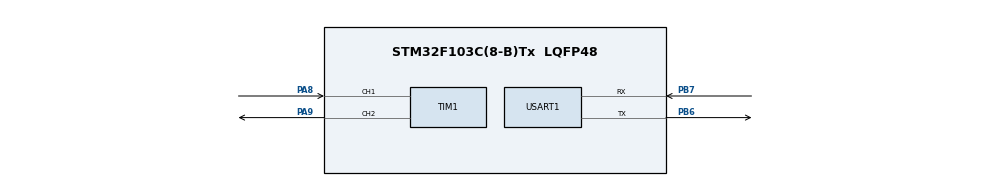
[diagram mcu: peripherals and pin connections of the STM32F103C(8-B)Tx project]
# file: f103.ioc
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Mcu.Family=STM32F1
Mcu.Name=STM32F103C(8-B)Tx
Mcu.Package=LQFP48
NVIC.PriorityGroup=NVIC_PRIORITYGROUP_4
PA13.Mode=Serial_Wire
PA13.Signal=SYS_JTMS-SWDIO
PA14.Mode=Serial_Wire
PA14.Signal=SYS_JTCK-SWCLK
PA8.Signal=S_TIM1_CH1
PA9.Signal=S_TIM1_CH2
PB6.Mode=Asynchronous
PB6.Signal=USART1_TX
PB7.Mode=Asynchronous
PB7.Signal=USART1_RX
PD0-OSC_IN.Mode=HSE-External-Oscillator
PD0-OSC_IN.Signal=RCC_OSC_IN
PD1-OSC_OUT.Mode=HSE-External-Oscillator
PD1-OSC_OUT.Signal=RCC_OSC_OUT
ProjectManager.HeapSize=0x200
ProjectManager.StackSize=0x400
ProjectManager.TargetToolchain=CMake
RCC.APB1Freq_Value=8000000
RCC.APB2Freq_Value=8000000
SH.S_TIM1_CH1.0=TIM1_CH1,Input_Capture1_from_TI1
SH.S_TIM1_CH2.0=TIM1_CH2,Output Compare2 CH2
TIM1.Channel-Input_Capture1_from_TI1=TIM_CHANNEL_1
TIM1.Channel-Output\ Compare2\ CH2=TIM_CHANNEL_2
USART1.VirtualMode=VM_ASYNC
board=custom

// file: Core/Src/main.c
/* USER CODE BEGIN Header */
/**
  ******************************************************************************
  * @file           : main.c
  * @brief          : Main program body
  ******************************************************************************
  * @attention
  *
  * Copyright (c) 2026 STMicroelectronics.
  * All rights reserved.
  *
  * This software is licensed under terms that can be found in the LICENSE file
  * in the root directory of this software component.
  * If no LICENSE file comes with this software, it is provided AS-IS.
  *
  ******************************************************************************
  */
/* USER CODE END Header */
#include "main.h"
#include "tim.h"
#include "usart.h"
#include "gpio.h"

void SystemClock_Config(void);

int main(void)
{

  /* MCU Configuration--------------------------------------------------------*/

  /* Reset of all peripherals, Initializes the Flash interface and the Systick. */
  HAL_Init();

  /* Configure the system clock */
  SystemClock_Config();

  /* Initialize all configured peripherals */
  MX_GPIO_Init();
  MX_USART1_UART_Init();
  MX_TIM1_Init();

  /* Infinite loop */
  while (1)
  {

  }
}

void SystemClock_Config(void)
{
  RCC_OscInitTypeDef RCC_OscInitStruct = {0};
  RCC_ClkInitTypeDef RCC_ClkInitStruct = {0};

  /** Initializes the RCC Oscillators according to the specified parameters
  * in the RCC_OscInitTypeDef structure.
  */
  RCC_OscInitStruct.OscillatorType = RCC_OSCILLATORTYPE_HSI;
  RCC_OscInitStruct.HSIState = RCC_HSI_ON;
  RCC_OscInitStruct.HSICalibrationValue = RCC_HSICALIBRATION_DEFAULT;
  RCC_OscInitStruct.PLL.PLLState = RCC_PLL_NONE;
  if (HAL_RCC_OscConfig(&RCC_OscInitStruct) != HAL_OK)
  {
    Error_Handler();
  }

  /** Initializes the CPU, AHB and APB buses clocks
  */
  RCC_ClkInitStruct.ClockType = RCC_CLOCKTYPE_HCLK|RCC_CLOCKTYPE_SYSCLK
                              |RCC_CLOCKTYPE_PCLK1|RCC_CLOCKTYPE_PCLK2;
  RCC_ClkInitStruct.SYSCLKSource = RCC_SYSCLKSOURCE_HSI;
  RCC_ClkInitStruct.AHBCLKDivider = RCC_SYSCLK_DIV1;
  RCC_ClkInitStruct.APB1CLKDivider = RCC_HCLK_DIV1;
  RCC_ClkInitStruct.APB2CLKDivider = RCC_HCLK_DIV1;

  if (HAL_RCC_ClockConfig(&RCC_ClkInitStruct, FLASH_LATENCY_0) != HAL_OK)
  {
    Error_Handler();
  }
}

/* USER CODE BEGIN 4 */
void HAL_TIM_IC_CaptureCallback(TIM_HandleTypeDef *htim)
{
  if (htim->Instance == TIM1 && htim->Channel == HAL_TIM_ACTIVE_CHANNEL_1)
  {
    __HAL_TIM_SET_COUNTER(&htim1, 0);
  }
}

/* USER CODE END 4 */

void Error_Handler(void)
{
  __disable_irq();
  while (1)
  {
  }
}
